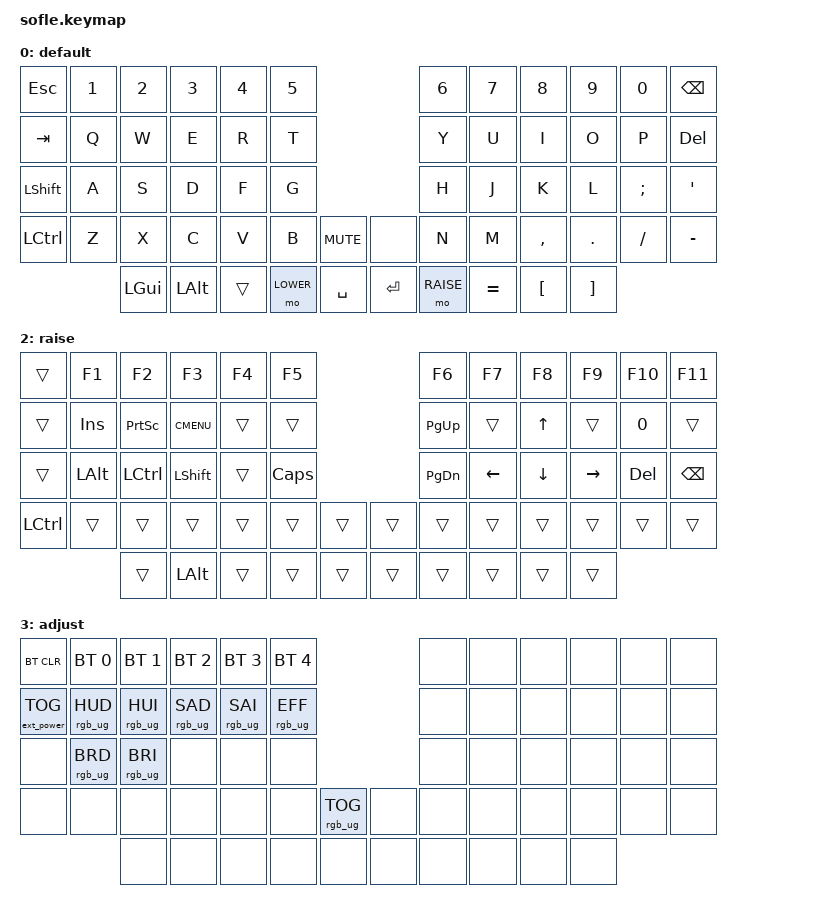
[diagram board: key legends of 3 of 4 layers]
/*
 * Copyright (c) 2020 The ZMK Contributors
 *
 * SPDX-License-Identifier: MIT
 */

#include <behaviors.dtsi>
#include <dt-bindings/zmk/keys.h>
#include <dt-bindings/zmk/bt.h>
#include <dt-bindings/zmk/rgb.h>
#include <dt-bindings/zmk/ext_power.h>

#define BASE 0
#define LOWER 1
#define RAISE 2
#define ADJUST 3

/ {

   // Activate ADJUST layer by pressing raise and lower
    conditional_layers {
        compatible = "zmk,conditional-layers";
        adjust_layer {
            if-layers = <LOWER RAISE>;
            then-layer = <ADJUST>;
        };
    };

    keymap {
        compatible = "zmk,keymap";

        default_layer {
            display-name = "default";
// ------------------------------------------------------------------------------------------------------------
// |  ESC   |  1  |  2  |   3  |  4   |  5   |                   |  6   |  7    |  8    |  9   |   0   | BKSPC |
// |  TAB   |  Q  |  W  |   E  |  R   |  T   |                   |  Y   |  U    |  I    |  O   |   P   |  DEL  |
// |  SHIFT |  A  |  S  |   D  |  F   |  G   |                   |  H   |  J    |  K    |  L   |   ;   |   '   |
// |  CTRL  |  Z  |  X  |   C  |  V   |  B   |  MUTE  |  |       |  N   |  M    |  ,    |  .   |   /   | MINUS |
//                | GUI | ALT  |     | LOWER | SPACE |  | ENTER | RAISE| EQUAL | LBKT  | RBKT |
            bindings = <
&kp ESC &kp N1 &kp N2   &kp N3   &kp N4    &kp N5                           &kp N6 &kp N7    &kp N8    &kp N9   &kp N0   &kp BSPC
&kp TAB &kp Q  &kp W    &kp E    &kp R     &kp T                            &kp Y  &kp U     &kp I     &kp O    &kp P    &kp DEL
&kp LSHFT &kp A  &kp S    &kp D    &kp F     &kp G                            &kp H  &kp J     &kp K     &kp L    &kp SEMI &kp SQT
&kp LCTRL &kp Z  &kp X    &kp C    &kp V     &kp B      &kp C_MUTE &none      &kp N  &kp M     &kp COMMA &kp DOT  &kp FSLH &kp MINUS
                 &kp LGUI &kp LALT &trans &mo LOWER &kp SPACE     &kp RET &mo RAISE  &kp EQUAL  &kp LBKT  &kp RBKT
            >;

            sensor-bindings = <&inc_dec_kp C_VOL_UP C_VOL_DN &inc_dec_kp PG_UP PG_DN>;
        };

        lower_layer {
            display-name = "lower";
// TODO: Some binds are waiting for shifted keycode support.
// ------------------------------------------------------------------------------------------------------------
// |   `   |  !  |  @  |  #   |  $   |  %   |                   |  ^   |  &    |  *    |  (   |   )   |   |   |
// |       |     |  ^  |      |      |      |                   |      |       |       |      |       |       |
// |  CLCK |  <- |  v  |  ->  |      |      |                   |      |       |       |      |       |       |
// |  CTRL | UNDO| CUT | COPY | PASTE|      |        |  |       |      |       |       |      |       |       |
//               |     |  ALT |      |      |        |  |       |      |       |       |      |
            bindings = <
&kp GRAVE &kp EXCL  &kp AT    &kp HASH    &kp DLLR  &kp PRCNT                 &kp CARET &kp AMPS &kp ASTRK &kp LPAR  &kp RPAR  &kp PIPE
&trans    &trans    &kp UP    &trans      &trans    &trans                    &trans    &trans   &trans    &trans    &trans    &trans
&kp CLCK  &kp LEFT  &kp DOWN  &kp RIGHT    &trans   &trans                    &trans    &trans   &trans    &trans    &trans    &trans
&kp LCTRL   &kp K_UNDO   &kp K_CUT    &kp K_COPY   &kp K_PASTE    &trans                    &trans    &trans   &trans    &trans    &trans    &trans
                    &trans    &kp LALT      &trans    &trans     &trans &trans  &trans    &trans   &trans    &trans
            >;

            sensor-bindings = <&inc_dec_kp C_VOL_UP C_VOL_DN &inc_dec_kp PG_UP PG_DN>;
        };

        raise_layer {
            display-name = "raise";
// ------------------------------------------------------------------------------------------------------------
// |       |  F1  |  F2  |  F3   |  F4   |  F5  |                |  F6  |  F7  |  F8   |  F9  |  F10  |  F11  |
// |       | INS  | PSCR | GUI   |       |      |                | PGUP |      |   ^   |      |       |       |
// |       | ALT  | CTRL | SHIFT |       | CAPS |                | PGDN |   <- |   v   |  ->  |  DEL  | BKSPC |
// |  CTRL |      |      |       |       |      |      |  |      |      |      |       |      |       |       |
//                |      |  ALT  |       |      |      |  |      |      |      |       |      |
            bindings = <
&trans     &kp F1       &kp F2       &kp F3       &kp F4       &kp F5                        &kp F6    &kp F7    &kp F8   &kp F9    &kp F10 &kp F11
&trans     &kp INS      &kp PSCRN    &kp K_CMENU  &trans       &trans                        &kp PG_UP &trans    &kp UP   &trans    &kp N0  &trans
&trans     &kp LALT     &kp LCTRL    &kp LSHFT    &trans       &kp CLCK                      &kp PG_DN &kp LEFT  &kp DOWN &kp RIGHT &kp DEL &kp BSPC
&kp LCTRL  &trans   &trans    &trans   &trans  &trans        &trans  &trans  &trans    &trans    &trans   &trans    &trans  &trans
                        &trans      &kp LALT       &trans       &trans        &trans  &trans  &trans    &trans    &trans   &trans
            >;

            sensor-bindings = <&inc_dec_kp C_VOL_UP C_VOL_DN &inc_dec_kp PG_UP PG_DN>;
        };

        adjust_layer {
// ----------------------------------------------------------------------------------------------------------------------------
// | BTCLR  |  BT1    |  BT2    |   BT3   |   BT4   |   BT5   |                  |      |      |       |      |       |       |
// | EXTPWR | RGB_HUD | RGB_HUI | RGB_SAD | RGB_SAI | RGB_EFF |                  |      |      |       |      |       |       |
// |        | RGB_BRD | RGB_BRI |         |         |         |                  |      |      |       |      |       |       |
// |        |         |         |         |         |         | RGB_TOG | |      |      |      |       |      |       |       |
//                    |         |         |         |         |         | |      |      |      |       |      |
            display-name = "adjust";
            bindings = <
&bt BT_CLR        &bt BT_SEL 0    &bt BT_SEL 1    &bt BT_SEL 2    &bt BT_SEL 3    &bt BT_SEL 4                            &none &none &none &none &none &none
&ext_power EP_TOG &rgb_ug RGB_HUD &rgb_ug RGB_HUI &rgb_ug RGB_SAD &rgb_ug RGB_SAI &rgb_ug RGB_EFF                         &none &none &none &none &none &none
&none             &rgb_ug RGB_BRD &rgb_ug RGB_BRI &none           &none           &none                                   &none &none &none &none &none &none
&none             &none           &none           &none           &none           &none            &rgb_ug RGB_TOG &none  &none &none &none &none &none &none
                                  &none           &none           &none           &none            &none           &none  &none &none &none &none
            >;
        };

    };
};
